# K32W061 register map
Vendor: nxp.com; File version: 1.0
CPU: CM4 r0p1, little endian, MPU, no FPU, VTOR, 3 interrupt priority bits
Registers are 32-bit, read-write, reset 0x0 unless marked. A register's access mark holds for its fields unless they carry their own. Offsets are from the block's base; [hi:lo] are bit positions.

## CIC_IRB — This is the description of component cic_irb. It is an Infra Red Blaster Controller with a VPB bus interface. More details will follow.
Base 0x40007000
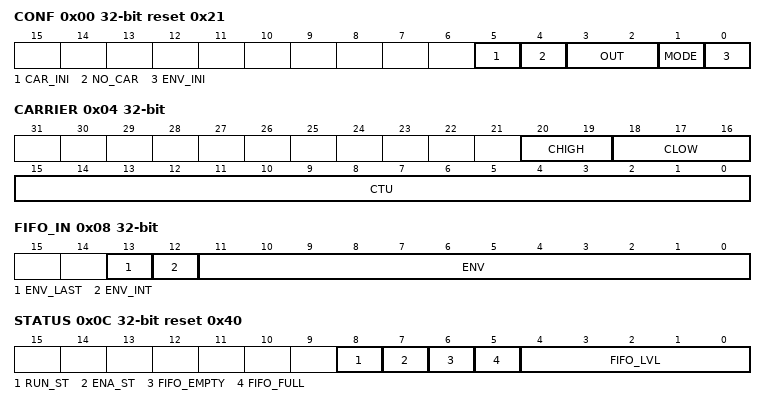
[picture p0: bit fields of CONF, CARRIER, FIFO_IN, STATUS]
0x00 CONF reset 0x21 — IR Blaster configuration
  [5] CAR_INI — Initial carrier value.
    0=ZERO (Carrier starts with '0' (the carrier is low during CHIGH[1:0] and high during CLOW[2:0])); 1=ONE (Carrier starts with '1' (the carrier is high during CHIGH[1:0] and low during CLOW[2:0]))
  [4] NO_CAR — No carrier
    0=NORMAL (Normal. IR_OUT = envelope + carrier); 1=STOP (Carrier is inhibited. IR_OUT = envelope only)
  [3:2] OUT — Output logic function
    0=AND (envelope AND carrier); 1=OR (envelope OR carrier); 2=NAND (envelope NAND carrier); 3=NOR (envelope NOR carrier)
  [1] MODE — Blaster mode
    0=NORMAL (Normal mode. IR Blaster will stop when it encouter an envelope with ENV_LAST bit = '1'); 1=AUTO (Automatic restart. IR Blaster will transmit all envelopes and stop only when FIFO becames empty. ENV_LAST bit only generates an interrupt but doesn't stop transmission.)
  [0] ENV_INI — Initial envelope value. This is the level of the first envelope after IR Blaster start or restart.
    0=LOW (First envelope will be a low level); 1=HIGH (First envelope will be a high level)
0x04 CARRIER — IR Blaster carrier configuration
  [20:19] CHIGH — Carrier high period Carrier high level duration = (CHIGH + 1) * CTU. It is recommended to modify this field when the blaster unit is disable (i.e when ENA_ST = '0' in STATUS register)
  [18:16] CLOW — Carrier low period. Carrier low level duration = (CLOW + 1) * CTU. It is recommended to modify this field when the blaster unit is disable (i.e when ENA_ST = '0' in STATUS register)
  [15:0] CTU — Carrier Time Unit (CTU) CTU = CTU * TIRCP, TIRCP = IR module clock period = 1/48MHz. Value 0x0 is equivalent to 0x1. It is recommended to modify this field when the blaster unit is disable (i.e when ENA_ST = '0' in STATUS register)
0x08 FIFO_IN — IR Blaster Envelope FIFO input
  [13] ENV_LAST — Last envelope.
    0=NOT_LAST (IR Blaster loads the next envelope when this envelope finishes.); 1=LAST (IR Blaster stops and generates an interrupt when this envelope is completly transmitted. If MODE = '1', then IR Blaster only generates an interrupt)
  [12] ENV_INT — Generate an interrupt when starting emission of the envelope
    0=NO_INT (Don't generate interrupt); 1=INT (Generate interrupt)
  [11:0] ENV — Envelope duration expressed in carrier period number. Tenvelope = ENV * (CHIGH + CLOW + 2 ) * CTU. Value 0x000 has the same behaviour has value 0x001.
0x0C STATUS ro reset 0x40 — IR Blaster Status
  [8] RUN_ST — IR Blaster run status
    0=NOT_RUNNING (IR Blaster is not running. Either transmission has not yet been started or it is finished.); 1=RUNNING (IR Blaster is running.)
  [7] ENA_ST — IR Blaster status
    0=DISABLE (IR Blaster is disabled); 1=ENABLE (IR Blaster is enabled)
  [6] FIFO_EMPTY — IR Blaster FIFO empty flag
    0=NOT_EMPTY (FIFO is not empty); 1=EMPTY (FIFO is empty (FIFO level = 000000))
  [5] FIFO_FULL — IR Blaster FIFO full flag
    0=NOT_FULL (FIFO is not full); 1=FULL (FIFO is full (FIFO level = 100000))
  [4:0] FIFO_LVL — Current IR Blaster FIFO level
    0=EMPTY (FIFO is empty); 16=FULL (FIFO is full)
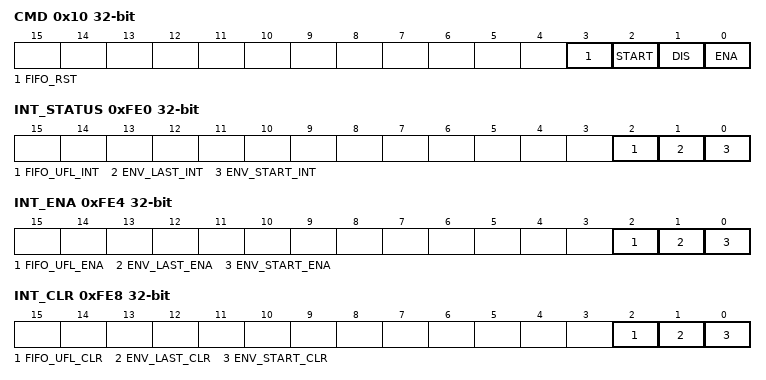
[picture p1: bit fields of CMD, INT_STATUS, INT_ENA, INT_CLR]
0x10 CMD reset not defined — IR Blaster Commands
  [3] FIFO_RST wo — Reset IR Blaster FIFO. This bit is self clearing.
    0=NO_EFFECT; 1=RESET (Reset FIFO. IR Blaster FIFO is completly re-initialized all data present in FIFO are erased.)
  [2] START wo — Start IR Blaster. This bit is self clearing.
    0=NO_EFFECT; 1=START (Start transmission Before setting this field, the blaster must be enable (the bit field ENA must be set first).)
  [1] DIS wo — Disable IR Blaster. This bit is self clearing.
    0=NO_EFFECT; 1=DISABLE (Disable IR Blaster. The transmission of envelopes is immediatly stopped. The FIFO is not reinitialized (the content of the FIFO is conserved).)
  [0] ENA wo — Enable IR Blaster. This bit is self clearing.
    0=NO_EFFECT; 1=ENABLE (Enable IR Blaster)
0xFE0 INT_STATUS ro — Interrupt Status
  [all] fields
    0=NOT_PENDING (Interrupt is not pending); 1=PENDING (Interrupt is pending)
  [2] FIFO_UFL_INT — IR Blaster FIFO underflow. IR Blaster has tried to transmit a data but the FIFO was empty.
  [1] ENV_LAST_INT — IR Blaster has finished to transmit an envelope with ENV_LAST bit = '1'.
  [0] ENV_START_INT — IR Blaster has started to transmit an envelope with ENV_INT bit = '1
0xFE4 INT_ENA — Interrupt Enable
  [2] FIFO_UFL_ENA — Enable/Disable FIFO_UFL interrupt
    0=DISABLE (Disable FIFO_UFL interrupt); 1=ENABLE (Enable FIFO_UFL nterrupt)
  [1] ENV_LAST_ENA — Enable/Disable ENV_LAST interrupt
    0=DISABLE (Disable ENV_LAST interrupt); 1=ENABLE (Enable ENV_LAST interrupt)
  [0] ENV_START_ENA — Enable/Disable ENV_START interrupt
    0=DISABLE (Disable ENV_START interrupt); 1=ENABLE (Enable ENV_START interrupt)
0xFE8 INT_CLR reset not defined — Interrupt Clear
  [2] FIFO_UFL_CLR wo — Clear FIFO_UFL interrupt
    0=NO_EFFECT; 1=CLEAR (clear FIFO_UFL interrupt This bit is self clearing)
  [1] ENV_LAST_CLR wo — Clear ENV_LAST interrupt
    0=NO_EFFECT; 1=CLEAR (clear ENV_LAST interrupt This bit is self clearing)
  [0] ENV_START_CLR wo — Clear ENV_START interrupt
    0=NO_EFFECT; 1=CLEAR (clear ENV_START interrupt This bit is self clearing)
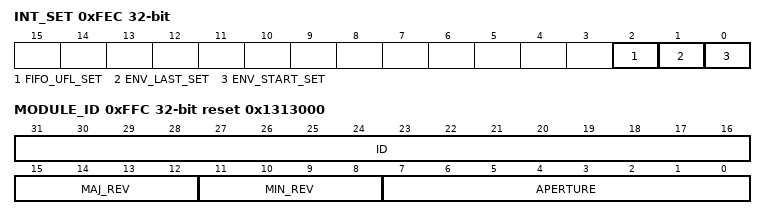
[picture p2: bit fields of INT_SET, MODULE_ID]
0xFEC INT_SET reset not defined — Interrupt Set
  [2] FIFO_UFL_SET wo — Set FIFO_UFL interrupt
    0=NO_EFFECT; 1=CLEAR (set FIFO_UFL interrupt This bit is self clearing)
  [1] ENV_LAST_SET wo — Set ENV_LAST interrupt
    0=NO_EFFECT; 1=CLEAR (set ENV_LAST interrupt This bit is self clearing)
  [0] ENV_START_SET wo — Set ENV_START interrupt
    0=NO_EFFECT; 1=CLEAR (set ENV_START interrupt This bit is self clearing)
0xFFC MODULE_ID ro reset 0x1313000 — IR Blaster Module Identifier
  [31:16] ID — Identifier. This is the unique identifier of the module
  [15:12] MAJ_REV — Major revision i.e. implies software modifications
  [11:8] MIN_REV — Minor revision i.e. with no software consequences
  [7:0] APERTURE — Aperture i.e. number minus 1 of consecutive packets 4 Kbytes reserved for this IP
